# ESP32S31_RADIO register map
Vendor: Espressif; Series: ESP32-S31; File version: 3.52
Registers are 32-bit, read-write, no defined reset value unless marked. A register's access mark holds for its fields unless they carry their own. Offsets are from the block's base; [hi:lo] are bit positions; {n}, {i} and the like mark numbered series; 'fields as' and 'values as' point back to an identical list.

## WIFI_MAC_AUX_TSF_CONTROL — SoftAP, NAN and broadcast-TWT TSF control words. Complete public leaves prove their addresses and exact enable/mode masks; unrelated bits and hardware transition rules remain unnamed.
Base 0x2010D860
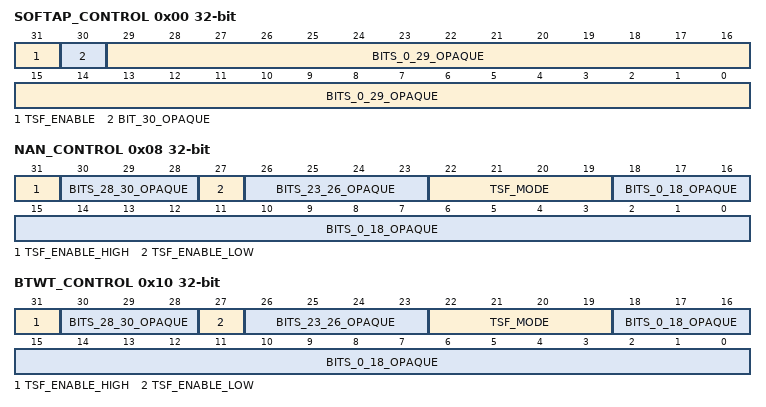
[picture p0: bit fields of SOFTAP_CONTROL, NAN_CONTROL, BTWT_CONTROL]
0x00 SOFTAP_CONTROL — Project-assigned name. Complete hal_disable_softap_tsf clears bits 31:30. Generic TSF enable/disable leaves independently identify bit 31 as the domain enable; bit 30 remains unknown.
  [31] TSF_ENABLE — Project-assigned name.
  [30] BIT_30_OPAQUE — Opaque: meaning not established.
  [29:0] BITS_0_29_OPAQUE — Opaque: meaning not established. Observed source use; the individual hardware meaning is unknown.
0x08 NAN_CONTROL — Project-assigned name. Complete NAN enable/disable leaves use the same two-stage gate and mode transaction as station TSF at this distinct word.
  [31] TSF_ENABLE_HIGH — Project-assigned name.
  [30:28] BITS_28_30_OPAQUE — Opaque: meaning not established. Observed source use; the individual hardware meaning is unknown.
  [27] TSF_ENABLE_LOW — Project-assigned name.
  [26:23] BITS_23_26_OPAQUE — Opaque: meaning not established. Observed source use; the individual hardware meaning is unknown.
  [22:19] TSF_MODE — Project-assigned name.
  [18:0] BITS_0_18_OPAQUE — Opaque: meaning not established. Observed source use; the individual hardware meaning is unknown.
0x10 BTWT_CONTROL — Project-assigned name. Complete hal_enable_sta_btwt_tsf enables or disables the broadcast-TWT TSF domain using the same gate and mode masks as station TSF.
  fields as NAN_CONTROL

## WIFI_MAC_TXRX_PREFIX — Eighteen direct fresh-read RMW edges before the first external HE callback in complete mac_txrx_init; complete hal_init later repeats the bit-28 set edge.
Base 0x201040FC
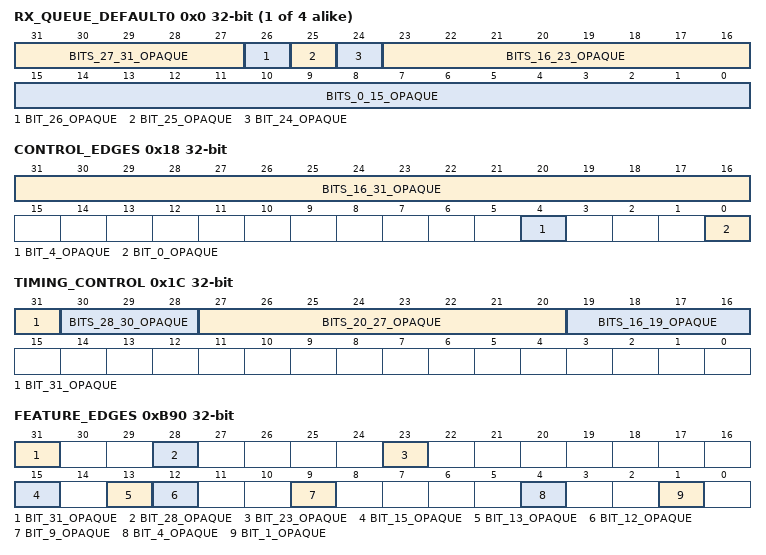
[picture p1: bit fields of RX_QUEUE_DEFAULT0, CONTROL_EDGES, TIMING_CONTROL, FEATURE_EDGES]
{0x0+4i} RX_QUEUE_DEFAULT{i} (i=0..3) — Project-assigned name. Four queue words have their high half cleared independently; queue zero and one then receive separate bit-24 and bit-26 set edges.
  [31:27] BITS_27_31_OPAQUE — Opaque: meaning not established.
  [26] BIT_26_OPAQUE — Opaque: meaning not established.
  [25] BIT_25_OPAQUE — Opaque: meaning not established.
  [24] BIT_24_OPAQUE — Opaque: meaning not established.
  [23:16] BITS_16_23_OPAQUE — Opaque: meaning not established.
  [15:0] BITS_0_15_OPAQUE — Opaque: meaning not established. Observed source use; the individual hardware meaning is unknown.
0x18 CONTROL_EDGES — Project-assigned name. Complete prefix sets bit 0, then bit 4 through a second fresh-read RMW.
  [31:16] BITS_16_31_OPAQUE — Opaque: meaning not established. Observed source use; the individual hardware meaning is unknown.
  [4] BIT_4_OPAQUE — Opaque: meaning not established.
  [0] BIT_0_OPAQUE — Opaque: meaning not established.
0x1C TIMING_CONTROL — Project-assigned name. Complete prefix sets bit 31, then replaces bits 27:20 with 0x1b in a separate RMW.
  [31] BIT_31_OPAQUE — Opaque: meaning not established.
  [30:28] BITS_28_30_OPAQUE — Opaque: meaning not established. Observed source use; the individual hardware meaning is unknown.
  [27:20] BITS_20_27_OPAQUE — Opaque: meaning not established.
  [19:16] BITS_16_19_OPAQUE — Opaque: meaning not established. Observed source use; the individual hardware meaning is unknown.
0xB90 FEATURE_EDGES — Project-assigned name. Four separately ordered prefix updates: first set bits 31,23,15,13 together; set bit 12; set bit 28; later set bit 9 after queue defaults. Complete hal_init repeats the bit-28 set after antenna initialization.
  [31] BIT_31_OPAQUE — Opaque: meaning not established.
  [28] BIT_28_OPAQUE — Opaque: meaning not established. Set once in mac_txrx_init and again at hal_init offset 0xe2 after the interrupt-mask store.
  [23] BIT_23_OPAQUE — Opaque: meaning not established.
  [15] BIT_15_OPAQUE — Opaque: meaning not established.
  [13] BIT_13_OPAQUE — Opaque: meaning not established.
  [12] BIT_12_OPAQUE — Opaque: meaning not established.
  [9] BIT_9_OPAQUE — Opaque: meaning not established.
  [4] BIT_4_OPAQUE — Opaque: meaning not established. Observed source use; the individual hardware meaning is unknown.
  [1] BIT_1_OPAQUE — Opaque: meaning not established. Observed source use; the individual hardware meaning is unknown.
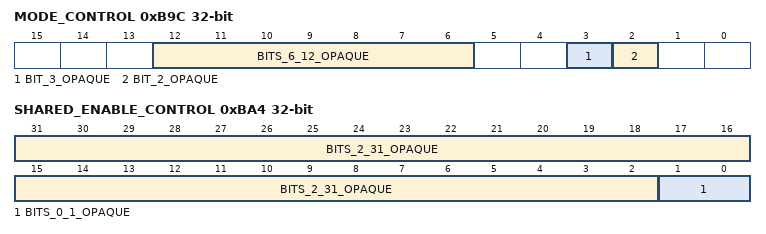
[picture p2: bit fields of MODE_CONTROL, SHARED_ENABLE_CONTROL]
0xB9C MODE_CONTROL — Project-assigned name. Canonical multifunction word. Complete mac_txrx prefix clears bit 3; the HE init suffix independently sets bit 2.
  [12:6] BITS_6_12_OPAQUE — Opaque: meaning not established. Observed source use; the individual hardware meaning is unknown.
  [3] BIT_3_OPAQUE — Opaque: meaning not established.
  [2] BIT_2_OPAQUE — Opaque: meaning not established. Complete HE init suffix sets bit 2.
0xBA4 SHARED_ENABLE_CONTROL — Project-assigned name. Final prefix RMW sets bits 1:0 together immediately before the first HE callback.
  [31:2] BITS_2_31_OPAQUE — Opaque: meaning not established. Observed source use; the individual hardware meaning is unknown.
  [1:0] BITS_0_1_OPAQUE — Opaque: meaning not established.
